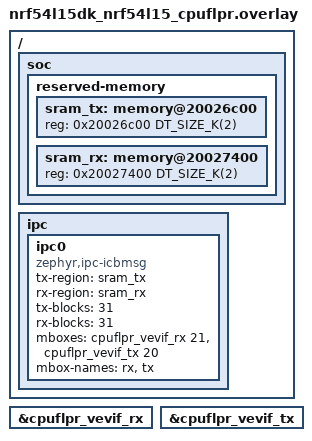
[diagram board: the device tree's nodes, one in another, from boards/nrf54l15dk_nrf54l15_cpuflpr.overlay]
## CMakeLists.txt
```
#
# Copyright (c) 2022 Nordic Semiconductor ASA
#
# SPDX-License-Identifier: Apache-2.0
#

cmake_minimum_required(VERSION 3.28.0)

find_package(Zephyr REQUIRED HINTS $ENV{ZEPHYR_BASE})
project(logging_multidomain_remote)

target_sources(app PRIVATE src/main.c)
```

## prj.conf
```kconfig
CONFIG_PRINTK=n
CONFIG_CONSOLE=n
CONFIG_UART_CONSOLE=n
CONFIG_SERIAL=n
CONFIG_BOOT_BANNER=n

CONFIG_IPC_SERVICE=y
CONFIG_MBOX=y

CONFIG_LOG=y
CONFIG_IPC_SERVICE_LOG_LEVEL_OFF=y
CONFIG_IPC_SERVICE_BACKEND_ICBMSG_LOG_LEVEL_OFF=y
CONFIG_LOG_BACKEND_IPC=y
CONFIG_LOG_PRINTK=n
CONFIG_LOG_BUFFER_SIZE=4096

CONFIG_ASSERT=y
CONFIG_LOG_BACKEND_UART=n
CONFIG_LOG_BACKEND_RTT=n

CONFIG_CPU_LOAD=y
```

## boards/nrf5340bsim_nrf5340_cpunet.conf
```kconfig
CONFIG_BUILD_OUTPUT_EXE=n

# For the mailbox to be initialized logger initialization is delayed like in real HW
CONFIG_LOG_PROCESS_THREAD=y
CONFIG_LOG_MODE_DEFERRED=y
CONFIG_LOG_BACKEND_NATIVE_POSIX=n
CONFIG_LOG_DOMAIN_NAME="net"
```

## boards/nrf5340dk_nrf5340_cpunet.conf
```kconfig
CONFIG_HEAP_MEM_POOL_SIZE=4096
```

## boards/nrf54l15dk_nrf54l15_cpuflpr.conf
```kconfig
CONFIG_PRINTK=n
CONFIG_CONSOLE=n
CONFIG_UART_CONSOLE=n
CONFIG_SERIAL=n
CONFIG_GPIO=n
CONFIG_CBPRINTF_CONVERT_CHECK_PTR=n
CONFIG_BOOT_BANNER=n
CONFIG_ASSERT=n
```

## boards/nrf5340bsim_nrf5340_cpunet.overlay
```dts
/*
 * Copyright (c) 2023 Nordic Semiconductor ASA
 *
 * SPDX-License-Identifier: Apache-2.0
 */

#include "nrf5340dk_nrf5340_cpunet.overlay"
```

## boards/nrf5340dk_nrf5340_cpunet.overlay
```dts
/*
 * Copyright (c) 2026 Nordic Semiconductor ASA
 *
 * SPDX-License-Identifier: Apache-2.0
 */

#include "nrf5340dk_nrf5340_cpunet_common.dtsi"

/ {
	reserved-memory {
		ranges;
		#address-cells = <1>;
		#size-cells = <1>;

		sram_rx: memory@20070000 {
			reg = <0x20070000 DT_SIZE_K(32)>;
		};

		sram_tx: memory@20078000 {
			reg = <0x20078000 DT_SIZE_K(32)>;
		};
	};

	ipc {
		ipc0: ipc0 {
			compatible = "zephyr,ipc-icbmsg";
			dcache-alignment = <8>;
			tx-region = <&sram_tx>;
			rx-region = <&sram_rx>;
			tx-blocks = <20>;
			rx-blocks = <20>;
			mboxes = <&mbox 0>, <&mbox 1>;
			mbox-names = "rx", "tx";
			status = "okay";
		};
	};
};
```

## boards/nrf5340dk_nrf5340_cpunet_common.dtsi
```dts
/*
 * Copyright (c) 2026 Nordic Semiconductor ASA
 *
 * SPDX-License-Identifier: Apache-2.0
 */

/delete-node/ &ipc0;
/delete-node/ &sram0_shared;

/ {
	chosen {
		/delete-property/ zephyr,ipc_shm;
	};
};
```

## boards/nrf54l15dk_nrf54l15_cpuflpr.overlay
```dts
/*
 * Copyright (c) 2026 Nordic Semiconductor ASA
 *
 * SPDX-License-Identifier: Apache-2.0
 */

/ {
	soc {
		reserved-memory {
			#address-cells = <1>;
			#size-cells = <1>;

			sram_tx: memory@20026c00 {
				reg = <0x20026c00 DT_SIZE_K(2)>;
			};

			sram_rx: memory@20027400 {
				reg = <0x20027400 DT_SIZE_K(2)>;
			};
		};
	};

	ipc {
		ipc0: ipc0 {
			compatible = "zephyr,ipc-icbmsg";
			tx-region = <&sram_tx>;
			rx-region = <&sram_rx>;
			tx-blocks = <31>;
			rx-blocks = <31>;
			mboxes = <&cpuflpr_vevif_rx 21>, <&cpuflpr_vevif_tx 20>;
			mbox-names = "rx", "tx";
			status = "okay";
		};
	};
};

&cpuflpr_vevif_rx {
	status = "okay";
};

&cpuflpr_vevif_tx {
	status = "okay";
};
```

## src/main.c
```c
/*
 * Copyright (c) 2022 Nordic Semiconductor ASA
 *
 * SPDX-License-Identifier: Apache-2.0
 */

#include <zephyr/kernel.h>
#include <zephyr/sys/printk.h>
#include <zephyr/logging/log.h>
#include <zephyr/ipc/ipc_service.h>
#include <zephyr/sys/cpu_load.h>
LOG_MODULE_REGISTER(app);

static volatile uint8_t sample_received_data;
static volatile bool ipc_ready;
static volatile bool ipc_bound;

static void timeout(struct k_timer *timer)
{
	static int cnt;

	LOG_INF("loop: %d", cnt++);
	if (cnt < 10) {
		k_timer_start(timer, K_MSEC(30), K_NO_WAIT);
	}
}

K_TIMER_DEFINE(timeout_timer, timeout, NULL);

static void ready_notify(volatile bool *ready)
{
	*ready = true;
}

static void ready_wait(volatile bool *ready)
{
	while (!*ready) {
		k_msleep(1);
	}
	*ready = false;
}
/*
 * ==> THREAD 1 (IPC instance 1) <==
 */

static void ept_bound(void *priv)
{
	ready_notify(&ipc_bound);
}

static void ept_recv(const void *data, size_t len, void *priv)
{
	sample_received_data = *((uint8_t *)data);

	ready_notify(&ipc_ready);
}

static const struct ipc_ept_cfg ept_cfg = {
	.name = "sample",
	.cb = {
			.bound = ept_bound,
			.received = ept_recv,
	},
};

static void ipc_run(void)
{
	const struct device *ipc_instance;
	unsigned char message = 0;
	struct ipc_ept ept;
	int ret;

	LOG_INF("IPC-service REMOTE [INST 1] demo started");

	ipc_instance = DEVICE_DT_GET(DT_NODELABEL(ipc0));

	/*k_sleep(K_FOREVER);*/
	ret = ipc_service_open_instance(ipc_instance);
	if (ret < 0 && ret != -EALREADY) {
		printk("ipc_service_open_instance() failure\n");
		return;
	}

	ret = ipc_service_register_endpoint(ipc_instance, &ept, &ept_cfg);
	if (ret < 0) {
		printk("ipc_service_register_endpoint() failure\n");
		return;
	}

	LOG_INF("wait for bound");
	ready_wait(&ipc_bound);
	LOG_INF("bounded");

	while (message < 9) {
		ready_wait(&ipc_ready);
		message = sample_received_data;

		LOG_INF("REMOTE [1]: %d", message);

		message++;

		ret = ipc_service_send(&ept, &message, sizeof(message));
		if (ret < 0) {
			printk("send_message(%d) failed with ret %d\n", message, ret);
			break;
		}

		k_msleep(10);
	}

	LOG_INF("IPC-service REMOTE [INST 1] demo ended.");
	if (IS_ENABLED(CONFIG_CPU_LOAD)) {
		int load = cpu_load_get(true);

		LOG_INF("CPU load: %d.%d%%", load / 10, load % 10);
	}
}

int main(void)
{
	if (IS_ENABLED(CONFIG_CPU_LOAD)) {
		(void)cpu_load_get(true);
	}

	k_timer_start(&timeout_timer, K_MSEC(30), K_NO_WAIT);

	ipc_run();

	k_sleep(K_FOREVER);

	return 0;
}
```

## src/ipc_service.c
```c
/*
 * Copyright (c) 2022 Nordic Semiconductor ASA
 *
 * SPDX-License-Identifier: Apache-2.0
 */

#include <zephyr/kernel.h>
#include <zephyr/device.h>
#include <zephyr/ipc/ipc_service.h>
#include <zephyr/logging/log.h>
#include <zephyr/sys/cpu_load.h>
LOG_MODULE_DECLARE(app);

#define STACKSIZE	2048
#define PRIORITY	K_PRIO_PREEMPT(2)

K_THREAD_STACK_DEFINE(sample_stack, STACKSIZE);
static volatile uint8_t sample_received_data;
static K_SEM_DEFINE(bound_sem, 0, 1);
static K_SEM_DEFINE(data_sem, 0, 1);

/*
 * ==> THREAD 1 (IPC instance 1) <==
 */

static void ept_bound(void *priv)
{
	k_sem_give(&bound_sem);
}

static void ept_recv(const void *data, size_t len, void *priv)
{
	sample_received_data = *((uint8_t *) data);

	k_sem_give(&data_sem);
}

static struct ipc_ept_cfg ept_cfg = {
	.name = "sample",
	.cb = {
		.bound    = ept_bound,
		.received = ept_recv,
	},
};

static void sample_entry(void *dummy0, void *dummy1, void *dummy2)
{
	ARG_UNUSED(dummy0);
	ARG_UNUSED(dummy1);
	ARG_UNUSED(dummy2);

	const struct device *ipc_instance;
	unsigned char message = 0;
	struct ipc_ept ept;
	int ret;
	int load = 0;
	int load_cnt = 0;

	printk("IPC-service REMOTE [INST 1] demo started\n");

	ipc_instance = DEVICE_DT_GET(DT_NODELABEL(ipc0));

	/*k_sleep(K_FOREVER);*/
	ret = ipc_service_open_instance(ipc_instance);
	if (ret < 0 && ret != -EALREADY) {
		printk("ipc_service_open_instance() failure\n");
		return;
	}

	ret = ipc_service_register_endpoint(ipc_instance, &ept, &ept_cfg);
	if (ret < 0) {
		printf("ipc_service_register_endpoint() failure\n");
		return;
	}

	LOG_INF("wait for bound");
	k_sem_take(&bound_sem, K_FOREVER);
	LOG_INF("bounded");

	if (IS_ENABLED(CONFIG_CPU_LOAD)) {
		(void)cpu_load_get(true);
	}

	while (message < 19) {
		k_sem_take(&data_sem, K_FOREVER);
		message = sample_received_data;

		LOG_INF("REMOTE [1]: %d", message);

		message++;

		ret = ipc_service_send(&ept, &message, sizeof(message));
		if (ret < 0) {
			printk("send_message(%d) failed with ret %d\n", message, ret);
			break;
		}

		k_msleep(10);
		load_cnt++;
		if (load_cnt % 10 == 0) {
			if (IS_ENABLED(CONFIG_CPU_LOAD)) {
				load = cpu_load_get(true);
				LOG_INF("CPU load: %d.%d%%", load / 10, load % 10);
			}
		}
	}

	printk("IPC-service REMOTE [INST 1] demo ended.\n");
}
K_THREAD_DEFINE(sample_thread_id, STACKSIZE, sample_entry, NULL, NULL, NULL, PRIORITY, 0, 0);
```
